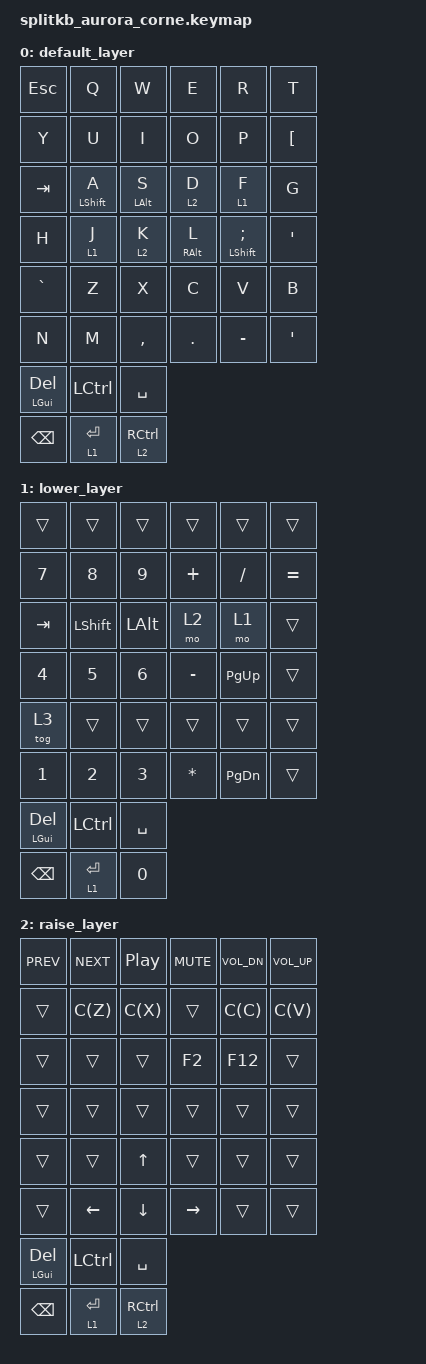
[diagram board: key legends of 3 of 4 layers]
/*
 * Copyright (c) 2020 The ZMK Contributors
 *
 * SPDX-License-Identifier: MIT
 */

#include <behaviors.dtsi>
#include <dt-bindings/zmk/keys.h>
#include <dt-bindings/zmk/bt.h>

/ {
    keymap {
            compatible = "zmk,keymap";

            default_layer {
            // -----------------------------------------------------------------------------------------
            // | ESC |  Q  |  W  |  E  |  R  |  T  |   |  Y  |  U  |  I  |  O  |  P  |  Å   |
            // | TAB | A/⇧ | S/A | D/R | F/L |  G  |   |  H  | J/L | K/R | L/A | Ö/⇧ |  Ä   |
            // |  <  |  Z  |  X  |  C  |  V  |  B  |   |  N  |  M  |  ,  |  .  |  -  |  "   |
            //                    | GUI | CTRL| SPC |   | BSPC| ENT/L| CTRL/R|
            // -----------------------------------------------------------------------------------------
            bindings = <
                &kp ESC       &kp Q          &kp W          &kp E          &kp R          &kp T
                &kp Y         &kp U          &kp I          &kp O          &kp P          &kp LBKT

                &kp TAB       &mt LSHFT A    &mt LALT S     &lt 2 D        &lt 1 F        &kp G
                &kp H         &lt 1 J        &lt 2 K        &mt RALT L     &mt LSHFT SEMI  &kp SQT

                &kp GRAVE     &kp Z          &kp X          &kp C          &kp V          &kp B
                &kp N         &kp M          &kp COMMA     &kp DOT        &kp MINUS      &kp SQT

                &mt LGUI DEL  &kp LCTRL      &kp SPACE
                &kp BSPC      &lt 1 RET      &lt 2 RCTRL
            >;
        };

        lower_layer {
            // -----------------------------------------------------------------------------------------
            // |     |     |     |     |     |     |   |  7  |  8  |  9  |  +  |  /  |  =   |
            // | TAB |  ⇧  | ALT | RSE | LWR |     |   |  4  |  5  |  6  |  -  | PGU |     |
            // | ADJ |     |     |     |     |     |   |  1  |  2  |  3  |  *  | PGD |     |
            //                    | GUI | CTRL| SPC |   | BSPC| ENT/L| 0|
            // -----------------------------------------------------------------------------------------
            bindings = <
                &trans        &trans        &trans        &trans        &trans        &trans
                &kp N7        &kp N8        &kp N9        &kp PLUS       &kp FSLH       &kp EQUAL

                &kp TAB       &kp LSHFT      &kp LALT       &mo 2          &mo 1          &trans
                &kp N4        &kp N5        &kp N6        &kp MINUS      &kp PG_UP      &trans

                &tog 3        &trans        &trans        &trans        &trans        &trans
                &kp N1        &kp N2        &kp N3        &kp ASTRK       &kp PG_DN      &trans

                &mt LGUI DEL  &kp LCTRL      &kp SPACE
                &kp BSPC      &lt 1 RET      &kp N0
            >;
        };

        raise_layer {
            // -----------------------------------------------------------------------------------------
            // | PREV| NEXT| PLAY| MUTE| VOL- | VOL+|   |     |     |     |     |     |     |
            // |     | UNDO| CUT |     | COPY |PASTE|   |     |     |  ↑  |     |     |     |
            // |     |     |     | F2  | F12  |     |   |     |  ←  |  ↓  |  →  |     |     |
            //                    | GUI | CTRL| SPC |   | BSPC| ENT/L| CTRL/R|
            // -----------------------------------------------------------------------------------------
            bindings = <
                &kp C_PREV    &kp C_NEXT    &kp C_PP    &kp C_MUTE    &kp C_VOL_DN    &kp C_VOL_UP
                &trans        &kp C(Z)       &kp C(X)       &trans        &kp C(C)       &kp C(V)
                &trans        &trans        &trans        &kp F2         &kp F12        &trans

                &trans        &trans        &trans        &trans        &trans        &trans
                &trans        &trans        &kp UP        &trans        &trans        &trans
                &trans        &kp LEFT       &kp DOWN      &kp RIGHT      &trans        &trans

                &mt LGUI DEL  &kp LCTRL      &kp SPACE
                &kp BSPC      &lt 1 RET      &lt 2 RCTRL
            >;
        };

        adjust_layer {
            // -----------------------------------------------------------------------------------------
            // |     |     |     |     |     |     |   |     |     |     |     |     |     |
            // |     |     |     |     |     |     |   |     |     |     |     |     |     |
            // |     |     |     |     |     |     |   |     |     |     |     |     |     |
            //                    |     |     |     |   |     |     |     |
            // -----------------------------------------------------------------------------------------
            bindings = <
                &trans        &trans        &trans        &trans        &trans        &trans
                &trans        &trans        &trans        &trans        &trans        &trans
                &trans        &trans        &trans        &trans        &trans        &trans

                &trans        &trans        &trans        &tog 3         &trans        &trans
                &trans        &trans        &trans        &trans        &trans        &trans

                &trans        &trans        &trans
                &trans        &trans        &trans
            >;
        };
    };
};
